# PY32F031xx register map
Vendor: Puya; Series: PY32F0; File version: 1.0.0
CPU: CM0+ r0p1, little endian, no MPU, no FPU, 4 interrupt priority bits
Registers are 32-bit, read-write, reset 0x0 unless marked. A register's access mark holds for its fields unless they carry their own. Offsets are from the block's base; [hi:lo] are bit positions; {n}, {i} and the like mark numbered series.

## OPA — Operational amplifier
Base 0x40010300
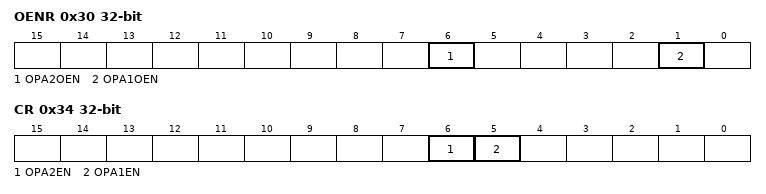
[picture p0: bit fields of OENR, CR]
0x30 OENR — OPA output enable register
  [6] OPA2OEN — OPA2 output enable
  [1] OPA1OEN — OPA1 output enable
0x34 CR — OPA control register
  [6] OPA2EN — OPA2 enable
  [5] OPA1EN — OPA1 enable

## PWR — Power control
Base 0x40007000
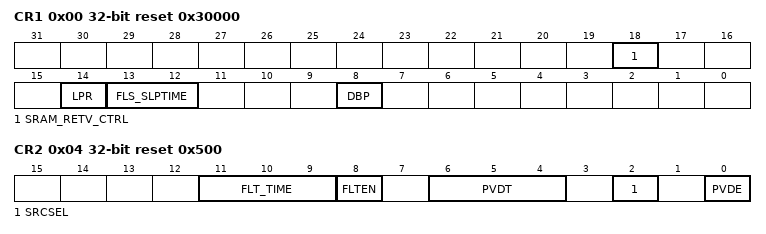
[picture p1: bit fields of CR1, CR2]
0x00 CR1 reset 0x30000 — Power control register 1
  [18] SRAM_RETV_CTRL — SRAMM retention voltage control
  [14] LPR — Low-power run
  [13:12] FLS_SLPTIME — Flash wait time after wakeup from the stop mode
  [8] DBP — Disable backup domain write protection
0x04 CR2 reset 0x500 — Power control register 2
  [11:9] FLT_TIME — Digital filter time configuration
  [8] FLTEN — Digital filter enable
  [6:4] PVDT — Power voltage detector threshold selection
  [2] SRCSEL — Power voltage detector volatage selection
  [0] PVDE — Power voltage detector enable
0x14 SR ro — Power status register
  [11] PVDO — PVD output

## GPIOA — General-purpose I/Os
Base 0x50000000
Same registers: GPIOB 0x50000400, GPIOF 0x50001400
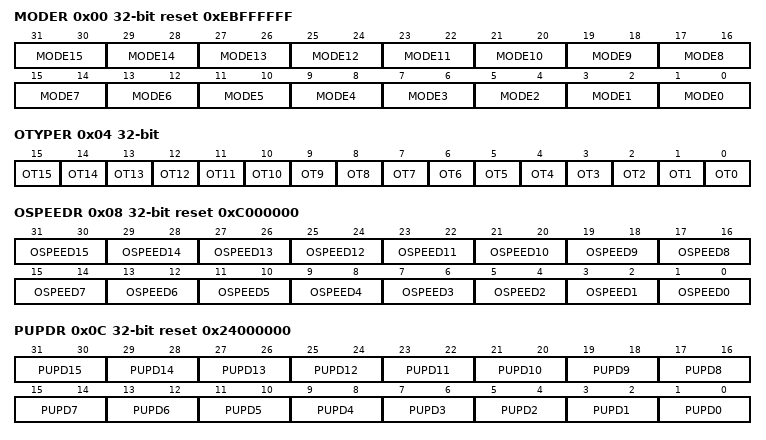
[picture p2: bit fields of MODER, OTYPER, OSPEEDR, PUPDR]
0x00 MODER reset 0xEBFFFFFF — GPIO port mode register
  [2n+1:2n] MODE{n} (n=0..15) — Port x configuration bits (y = 0..15)
0x04 OTYPER — GPIO port output type register
  [n] OT{n} (n=0..15) — Port x configuration bits (y = 0..15)
0x08 OSPEEDR reset 0xC000000 — GPIO port output speed register
  [2n+1:2n] OSPEED{n} (n=0..15) — Port x configuration bits (y = 0..15)
0x0C PUPDR reset 0x24000000 — GPIO port pull-up/pull-down register
  [2n+1:2n] PUPD{n} (n=0..15) — Port x configuration bits (y = 0..15)
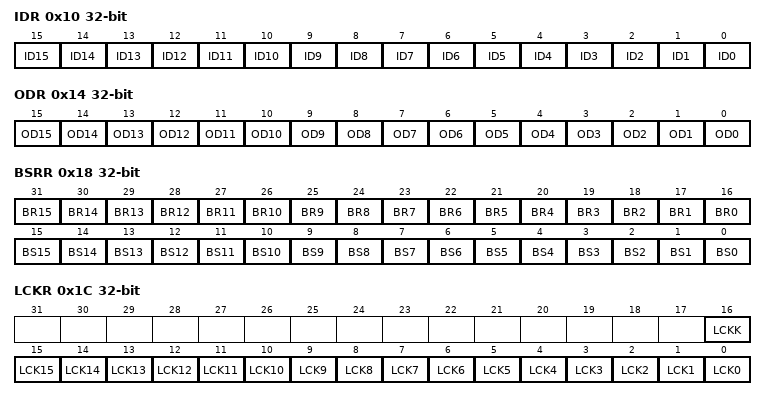
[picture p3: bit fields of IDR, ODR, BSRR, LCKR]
0x10 IDR ro — GPIO port input data register
  [n] ID{n} (n=0..15) — Port input data (y = 0..15)
0x14 ODR — GPIO port output data register
  [n] OD{n} (n=0..15) — Port output data (y = 0..15)
0x18 BSRR wo — GPIO port bit set/reset register
  [n+16] BR{n} (n=1..15) — Port x reset bit y (y = 0..15)
  [16] BR0 — Port x set bit y (y= 0..15)
  [n] BS{n} (n=0..15) — Port x set bit y (y= 0..15)
0x1C LCKR — GPIO port configuration lock register
  [16] LCKK — Port x lock bit y (y= 0..15)
  [n] LCK{n} (n=0..15) — Port x lock bit y (y= 0..15)
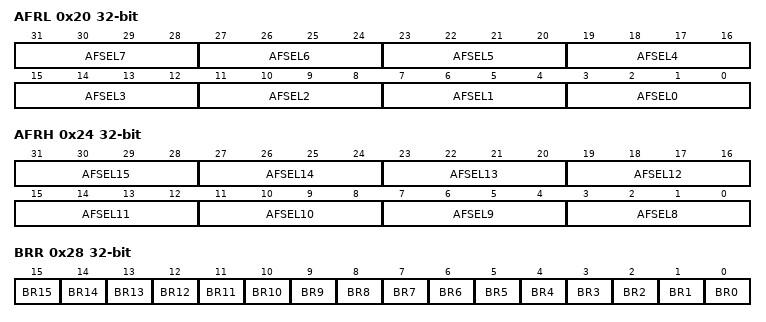
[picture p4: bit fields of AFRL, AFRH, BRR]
0x20 AFRL — GPIO alternate function low register
  [4n+3:4n] AFSEL{n} (n=0..7) — Alternate function selection for port x bit y (y = 0..7)
0x24 AFRH — GPIO alternate function high register
  [4n-29:4n-32] AFSEL{n} (n=8..15) — Alternate function selection for port x bit y (y = 8..15)
0x28 BRR wo — port bit reset register
  [n] BR{n} (n=0..15) — Port Reset bit

## EXTI — External interrupt/event controller
Base 0x40021800
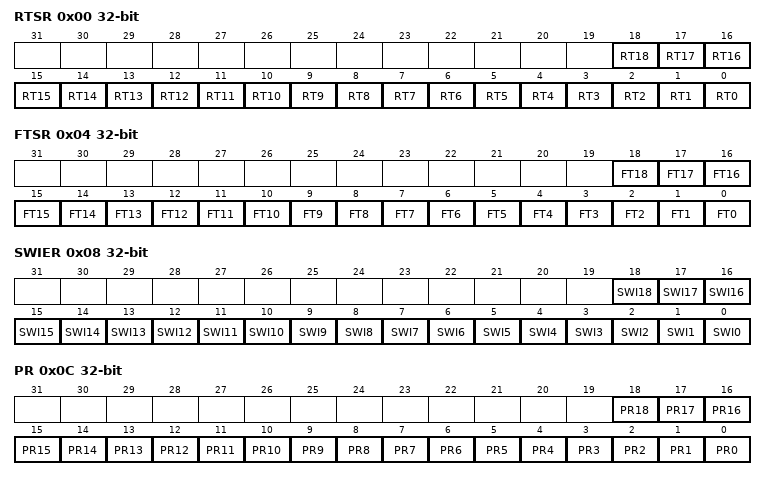
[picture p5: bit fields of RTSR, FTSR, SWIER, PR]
0x00 RTSR — EXTI rising trigger selection register
  [n] RT{n} (n=0..18) — Rising trigger event configuration bit of Configurable Event input
0x04 FTSR — EXTI falling trigger selection register
  [n] FT{n} (n=0..18) — Falling trigger event configuration bit of Configurable Event input
0x08 SWIER — EXTI software interrupt event register
  [n] SWI{n} (n=0..18) — Rising trigger event configuration bit of Configurable Event input
0x0C PR — EXTI pending register
  [n] PR{n} (n=14..18) — configurable event inputs x rising edge Pending bit.
  [13] PR13 — configurable event inputs x rising edge Pending bit
  [n] PR{n} (n=0..12) — configurable event inputs x rising edge Pending bit.
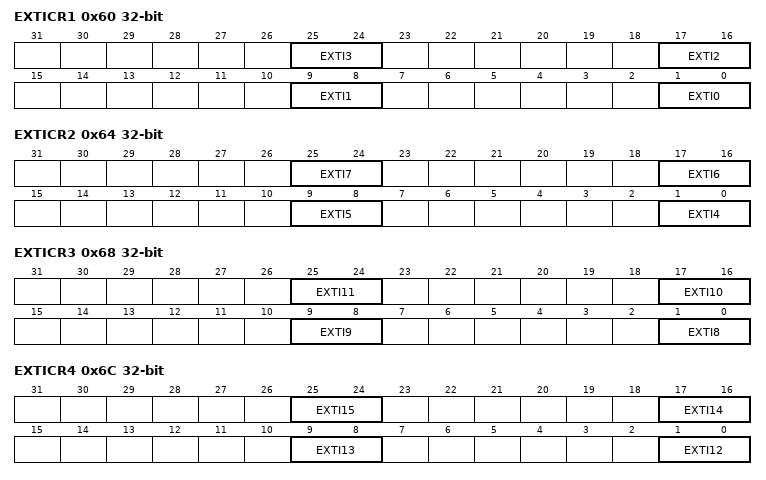
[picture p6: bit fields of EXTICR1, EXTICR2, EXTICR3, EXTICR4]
0x60 EXTICR1 — EXTI external interrupt selection register
  [8n+1:8n] EXTI{n} (n=0..3) — GPIO port selection
0x64 EXTICR2 — EXTI external interrupt selection register
  [8n-31:8n-32] EXTI{n} (n=4..7) — GPIO port selection
0x68 EXTICR3 — EXTI external interrupt selection register
  [8n-63:8n-64] EXTI{n} (n=8..11) — GPIO port selection
0x6C EXTICR4 — EXTI external interrupt selection register
  [8n-95:8n-96] EXTI{n} (n=12..15) — GPIO port selection
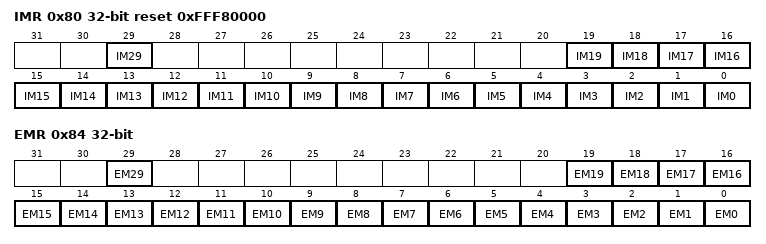
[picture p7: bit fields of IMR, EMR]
0x80 IMR reset 0xFFF80000 — EXTI CPU wakeup with interrupt mask register
  [29] IM29 — CPU wakeup with interrupt mask on event input
  [n] IM{n} (n=0..19) — CPU wakeup with interrupt mask on event input
0x84 EMR — EXTI CPU wakeup with event mask register
  [29] EM29 — CPU wakeup with event mask on event input
  [n] EM{n} (n=0..19) — CPU wakeup with event mask on event input
